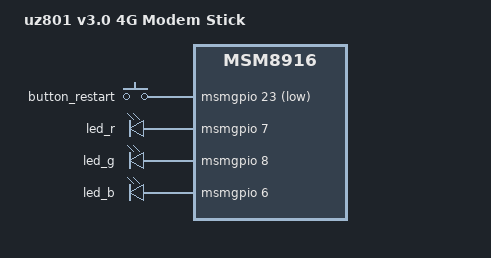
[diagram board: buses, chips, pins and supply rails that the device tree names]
// SPDX-License-Identifier: GPL-2.0-only

/dts-v1/;

#include "msm8916-ufi.dtsi"

/ {
	model = "uz801 v3.0 4G Modem Stick";
	compatible = "yiming,uz801-v3", "qcom,msm8916";
};

&button_restart {
	gpios = <&msmgpio 23 GPIO_ACTIVE_LOW>;
};

&led_r {
	gpios = <&msmgpio 7 GPIO_ACTIVE_HIGH>;
};

&led_g {
	gpios = <&msmgpio 8 GPIO_ACTIVE_HIGH>;
};

&led_b {
	gpios = <&msmgpio 6 GPIO_ACTIVE_HIGH>;
};

&button_default {
	pins = "gpio23";
	bias-pull-up;
};

&gpio_leds_default {
	pins = "gpio6", "gpio7", "gpio8";
};


&memshare {
        /delete-property/ qcom,legacy-client;
};

&cpu_opp_table {
        /delete-node/ opp-998400000;
        /delete-node/ opp-1094400000;
        /delete-node/ opp-1152000000;
        /delete-node/ opp-1209600000;
};

/delete-node/ &memshare_gps;
/delete-node/ &gps_mem;
/delete-node/ &mdss;
/delete-node/ &gpu;
/delete-node/ &gpu_iommu;
/delete-node/ &sound;
/delete-node/ &lpass;
/delete-node/ &lpass_codec;
/delete-node/ &wcnss_bt;
/delete-node/ &pm8916_codec;
/delete-node/ &venus;
/delete-node/ &venus_mem;
/delete-node/ &camss;
/delete-node/ &{/thermal-zones/gpu-thermal};
/delete-node/ &{/thermal-zones/camera-thermal};
